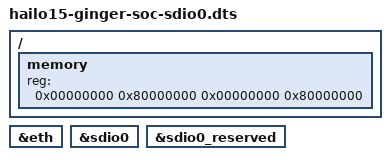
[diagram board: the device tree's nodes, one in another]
// SPDX-License-Identifier:     GPL-2.0
/*
 * Copyright (c) 2019-2023 Hailo Technologies Ltd. All rights reserved.
 */

/dts-v1/;

#include "hailo15-base.dtsi"

/ {
    memory {
        device_type = "memory";
        reg = <0x00000000 0x80000000 0x00000000 0x80000000>;
    };
};

&eth {
    status = "okay";
};

&sdio0 {
    status = "okay";
};

&sdio0_reserved {
    status = "okay";
};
